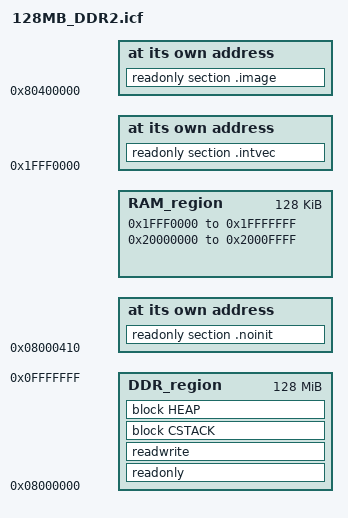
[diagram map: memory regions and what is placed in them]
/*###ICF### Section handled by ICF editor, don't touch! ****/
/*-Editor annotation file-*/
/* IcfEditorFile="$TOOLKIT_DIR$\config\ide\IcfEditor\cortex_v1_0.xml" */
/*-Specials-*/
define symbol __ICFEDIT_intvec_start__ = 0x1fff0000;
define symbol __image_start__ = 0x80400000;
/*-Memory Regions-*/
define symbol __ICFEDIT_region_ROM_start__ = 0x0;
define symbol __ICFEDIT_region_ROM_end__   = 0x0;
define symbol __ICFEDIT_region_RAM_start__ = 0x1fff0000;
define symbol __ICFEDIT_region_RAM_end__   = 0x1fffffff;
/*-Sizes-*/
define symbol __ICFEDIT_size_cstack__ = 0x400;
define symbol __ICFEDIT_size_heap__   = 0x800;
/**** End of ICF editor section. ###ICF###*/

define symbol __region_DDR_start__ = 0x08000000;
define symbol __region_DDR_end__ = 0x0fffffff;

define symbol __region_RAM2_start__ = 0x20000000;
define symbol __region_RAM2_end__ = 0x2000ffff;

define exported symbol __VECTOR_TABLE = 0x1fff0000;
define exported symbol __VECTOR_RAM = 0x1fff0000;


define symbol __code_start__ = 0x08000410;

define memory mem with size = 4G;
define region ROM_region   = mem:[from __ICFEDIT_region_ROM_start__   to __ICFEDIT_region_ROM_end__];
define region RAM_region   = mem:[from __ICFEDIT_region_RAM_start__   to __ICFEDIT_region_RAM_end__] | mem:[from __region_RAM2_start__ to __region_RAM2_end__];
define region DDR_region   = mem:[from __region_DDR_start__   to __region_DDR_end__];

define block CSTACK    with alignment = 8, size = __ICFEDIT_size_cstack__   { };
define block HEAP      with alignment = 8, size = __ICFEDIT_size_heap__     { };

initialize by copy { readwrite };
do not initialize  { section .noinit };
    
place at address mem:__image_start__ { readonly section .image };
place at address mem:__ICFEDIT_intvec_start__ { readonly section .intvec };
place at address mem:__code_start__ { readonly section .noinit };

place in DDR_region   { readonly };

place in DDR_region   { readwrite,
                        block CSTACK, block HEAP };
